AUTOSAR XML (schema 4-0-3)
standard types defined: Boolean, UInt16
package /AUTOSAR_Platform/DataConstrs
  range DC_Boolean: raw 0..1
  range DC_UInt16: raw 0..65535
package /PATAC/MSM/ComponentTypes
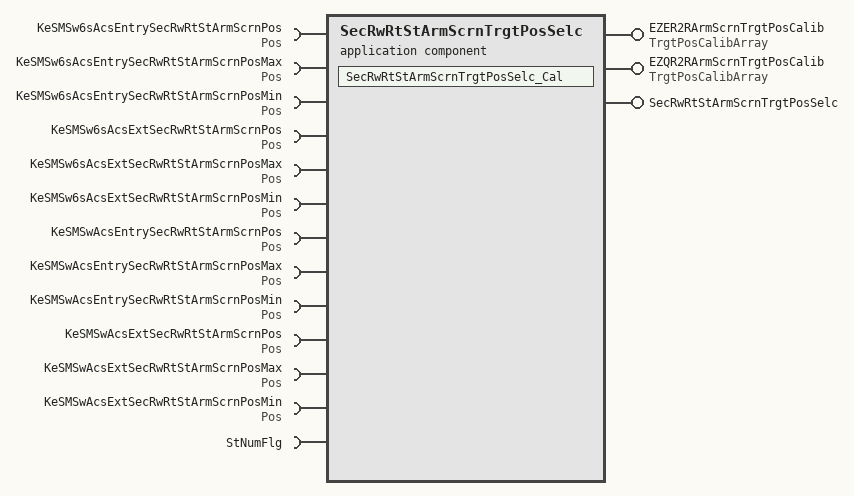
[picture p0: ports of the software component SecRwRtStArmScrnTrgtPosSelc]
  application sw component type SecRwRtStArmScrnTrgtPosSelc
    provide port EZER2RArmScrnTrgtPosCalib: nonqueued-sender-com-spec{data-element=TrgtPosArray, init-value=[4095, 4095, 4095]}, provided-interface=TrgtPosCalibArray
    provide port EZQR2RArmScrnTrgtPosCalib: nonqueued-sender-com-spec{data-element=TrgtPosArray, init-value=[4095, 4095, 4095]}, provided-interface=TrgtPosCalibArray
    provide port SecRwRtStArmScrnTrgtPosSelc: server-com-spec{operation=Cal, queue-length=1}, provided-interface=SecRwRtStArmScrnTrgtPosSelc
    13 x require port:
      KeSMSw6sAcsEntrySecRwRtStArmScrnPos: parameter-require-com-spec{init-value=0, parameter=Val}, required-interface=Pos
      KeSMSw6sAcsEntrySecRwRtStArmScrnPosMax: parameter-require-com-spec{init-value=0, parameter=Val}, required-interface=Pos
      KeSMSw6sAcsEntrySecRwRtStArmScrnPosMin: parameter-require-com-spec{init-value=0, parameter=Val}, required-interface=Pos
      KeSMSw6sAcsExtSecRwRtStArmScrnPos: parameter-require-com-spec{init-value=0, parameter=Val}, required-interface=Pos
      KeSMSw6sAcsExtSecRwRtStArmScrnPosMax: parameter-require-com-spec{init-value=0, parameter=Val}, required-interface=Pos
      KeSMSw6sAcsExtSecRwRtStArmScrnPosMin: parameter-require-com-spec{init-value=0, parameter=Val}, required-interface=Pos
      KeSMSwAcsEntrySecRwRtStArmScrnPos: parameter-require-com-spec{init-value=0, parameter=Val}, required-interface=Pos
      KeSMSwAcsEntrySecRwRtStArmScrnPosMax: parameter-require-com-spec{init-value=0, parameter=Val}, required-interface=Pos
      KeSMSwAcsEntrySecRwRtStArmScrnPosMin: parameter-require-com-spec{init-value=0, parameter=Val}, required-interface=Pos
      KeSMSwAcsExtSecRwRtStArmScrnPos: parameter-require-com-spec{init-value=0, parameter=Val}, required-interface=Pos
      KeSMSwAcsExtSecRwRtStArmScrnPosMax: parameter-require-com-spec{init-value=0, parameter=Val}, required-interface=Pos
      KeSMSwAcsExtSecRwRtStArmScrnPosMin: parameter-require-com-spec{init-value=0, parameter=Val}, required-interface=Pos
      StNumFlg: required-interface=StNumFlg
        required-com-specs:
          data-element=Is4s, filter=data-filter-type=ALWAYS, init-value=0
          data-element=Is6s, filter=data-filter-type=ALWAYS, init-value=0
          data-element=Is6s7s, filter=data-filter-type=ALWAYS, init-value=0
          data-element=Is7s, filter=data-filter-type=ALWAYS, init-value=0
    behavior SecRwRtStArmScrnTrgtPosSelc_InternalBehavior
      operation invoked event OIT_SecRwRtStArmScrnTrgtPosSelc_Cal_SecRwRtStArmScrnTrgtPosSelc_Cal: start-on-event=SecRwRtStArmScrnTrgtPosSelc_Cal, operation=SecRwRtStArmScrnTrgtPosSelc.Cal
      runnable SecRwRtStArmScrnTrgtPosSelc_Cal
        data-receive-point-by-arguments:
          4 x access:
            REC_StNumFlg_Is4s: accessed-variable=StNumFlg.Is4s
            REC_StNumFlg_Is6s: accessed-variable=StNumFlg.Is6s
            REC_StNumFlg_Is6s7s: accessed-variable=StNumFlg.Is6s7s
            REC_StNumFlg_Is7s: accessed-variable=StNumFlg.Is7s
        data-send-points:
          access SEND_EZER2RArmScrnTrgtPosCalib_TrgtPosArray: accessed-variable=EZER2RArmScrnTrgtPosCalib.TrgtPosArray
          access SEND_EZQR2RArmScrnTrgtPosCalib_TrgtPosArray: accessed-variable=EZQR2RArmScrnTrgtPosCalib.TrgtPosArray
        12 x parameter access:
          PA_KeSMSw6sAcsEntrySecRwRtStArmScrnPos_Val: accessed-parameter=KeSMSw6sAcsEntrySecRwRtStArmScrnPos.Val
          PA_KeSMSw6sAcsEntrySecRwRtStArmScrnPosMax_Val: accessed-parameter=KeSMSw6sAcsEntrySecRwRtStArmScrnPosMax.Val
          PA_KeSMSw6sAcsEntrySecRwRtStArmScrnPosMin_Val: accessed-parameter=KeSMSw6sAcsEntrySecRwRtStArmScrnPosMin.Val
          PA_KeSMSw6sAcsExtSecRwRtStArmScrnPos_Val: accessed-parameter=KeSMSw6sAcsExtSecRwRtStArmScrnPos.Val
          PA_KeSMSw6sAcsExtSecRwRtStArmScrnPosMax_Val: accessed-parameter=KeSMSw6sAcsExtSecRwRtStArmScrnPosMax.Val
          PA_KeSMSw6sAcsExtSecRwRtStArmScrnPosMin_Val: accessed-parameter=KeSMSw6sAcsExtSecRwRtStArmScrnPosMin.Val
          PA_KeSMSwAcsEntrySecRwRtStArmScrnPos_Val: accessed-parameter=KeSMSwAcsEntrySecRwRtStArmScrnPos.Val
          PA_KeSMSwAcsEntrySecRwRtStArmScrnPosMax_Val: accessed-parameter=KeSMSwAcsEntrySecRwRtStArmScrnPosMax.Val
          PA_KeSMSwAcsEntrySecRwRtStArmScrnPosMin_Val: accessed-parameter=KeSMSwAcsEntrySecRwRtStArmScrnPosMin.Val
          PA_KeSMSwAcsExtSecRwRtStArmScrnPos_Val: accessed-parameter=KeSMSwAcsExtSecRwRtStArmScrnPos.Val
          PA_KeSMSwAcsExtSecRwRtStArmScrnPosMax_Val: accessed-parameter=KeSMSwAcsExtSecRwRtStArmScrnPosMax.Val
          PA_KeSMSwAcsExtSecRwRtStArmScrnPosMin_Val: accessed-parameter=KeSMSwAcsExtSecRwRtStArmScrnPosMin.Val
  swc implementation SecRwRtStArmScrnTrgtPosSelc_Implementation: behavior=SecRwRtStArmScrnTrgtPosSelc_InternalBehavior
    code-descriptors:
      code Default: artifact-descriptors=autosar-engineering-object={short-label=Default, category=SWSRC}
package /PATAC/MSM/ModeAdjust/CalPortInterface
  parameter interface Pos
    parameter data prototype Val: sw-calibration-access=READ-WRITE, type=UInt16
package /PATAC/MSM/ModeAdjust/DataType
  impl type TrgtPosCalibArray: category=ARRAY, sw-calibration-access=READ-ONLY, type-emitter=RTE  # 0:pos 1:max 2:min
    element Element: array-size=3, array-size-semantics=FIXED-SIZE, implementation-data-type=UInt16, invalid-value=0
package /PATAC/MSM/ModeAdjust/PortInterface
  client server interface SecRwRtStArmScrnTrgtPosSelc
    operation Cal
  sender receiver interface StNumFlg
    4 x data, all with type=Boolean:
      Is4s
      Is6s
      Is6s7s
      Is7s
    invalidation-policys:
      data-element=Is7s, handle-invalid=DONT-INVALIDATE
      data-element=Is6s, handle-invalid=DONT-INVALIDATE
      data-element=Is4s, handle-invalid=DONT-INVALIDATE
      data-element=Is6s7s, handle-invalid=DONT-INVALIDATE
  sender receiver interface TrgtPosCalibArray: invalidation-policy{data-element=TrgtPosArray, handle-invalid=DONT-INVALIDATE}
    data TrgtPosArray: type=TrgtPosCalibArray  # 0:Pos 1:Max 2:Min
